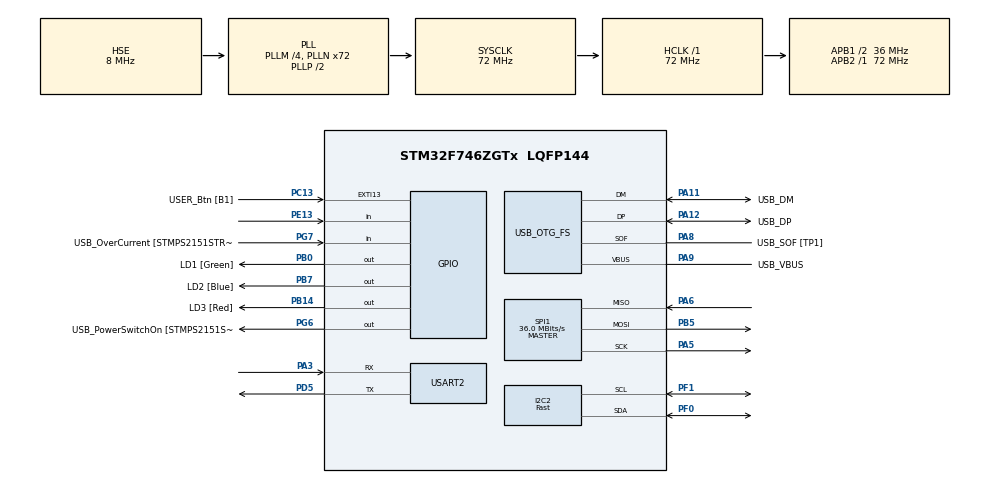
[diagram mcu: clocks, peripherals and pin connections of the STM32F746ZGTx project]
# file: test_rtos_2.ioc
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FREERTOS.Tasks01=defaultTask,24,128,StartDefaultTask,Default,NULL,Dynamic,NULL,NULL;myTask02,8,128,Sensor_Reading_Task,Default,NULL,Dynamic,NULL,NULL;myTask03,8,128,StartTask03,Default,NULL,Dynamic,NULL,NULL;myTask04,8,128,StartTask04,Default,NULL,Dynamic,NULL,NULL
I2C2.I2C_Speed_Mode=I2C_Fast
I2C2.Timing=0x00301739
Mcu.Family=STM32F7
Mcu.Name=STM32F746ZGTx
Mcu.Package=LQFP144
NVIC.PriorityGroup=NVIC_PRIORITYGROUP_4
NVIC.TIM1_UP_TIM10_IRQn=true\:0\:0\:false\:false\:true\:false\:false\:true
NVIC.TimeBase=TIM1_UP_TIM10_IRQn
NVIC.TimeBaseIP=TIM1
PA1.GPIO_Label=RMII_REF_CLK [LAN8742A-CZ-TR_REFCLK0]
PA1.Signal=ETH_REF_CLK
PA10.GPIO_Label=USB_ID
PA10.Signal=USB_OTG_FS_ID
PA11.GPIO_Label=USB_DM
PA11.Mode=Device_Only
PA11.Signal=USB_OTG_FS_DM
PA12.GPIO_Label=USB_DP
PA12.Mode=Device_Only
PA12.Signal=USB_OTG_FS_DP
PA13.GPIO_Label=TMS
PA13.Mode=Serial_Wire
PA13.Signal=SYS_JTMS-SWDIO
PA14.GPIO_Label=TCK
PA14.Mode=Serial_Wire
PA14.Signal=SYS_JTCK-SWCLK
PA2.GPIO_Label=RMII_MDIO [LAN8742A-CZ-TR_MDIO]
PA2.Signal=ETH_MDIO
PA3.Mode=Asynchronous
PA3.Signal=USART2_RX
PA5.Mode=Full_Duplex_Master
PA5.Signal=SPI1_SCK
PA6.Mode=Full_Duplex_Master
PA6.Signal=SPI1_MISO
PA7.GPIO_Label=RMII_CRS_DV [LAN8742A-CZ-TR_CRS_DV]
PA7.Signal=ETH_CRS_DV
PA8.GPIO_Label=USB_SOF [TP1]
PA8.Mode=Activate_SOF_FS
PA8.Signal=USB_OTG_FS_SOF
PA9.GPIO_Label=USB_VBUS
PA9.Mode=Activate_VBUS
PA9.Signal=USB_OTG_FS_VBUS
PB0.GPIO_Label=LD1 [Green]
PB0.Signal=GPIO_Output
PB13.GPIO_Label=RMII_TXD1 [LAN8742A-CZ-TR_TXD1]
PB13.Signal=ETH_TXD1
PB14.GPIO_Label=LD3 [Red]
PB14.Signal=GPIO_Output
PB3.GPIO_Label=SW0
PB3.Signal=SYS_JTDO-SWO
PB5.Mode=Full_Duplex_Master
PB5.Signal=SPI1_MOSI
PB7.GPIO_Label=LD2 [Blue]
PB7.Signal=GPIO_Output
PC1.GPIO_Label=RMII_MDC [LAN8742A-CZ-TR_MDC]
PC1.Signal=ETH_MDC
PC13.GPIO_Label=USER_Btn [B1]
PC13.Signal=GPXTI13
PC14/OSC32_IN.Mode=LSE-External-Oscillator
PC14/OSC32_IN.Signal=RCC_OSC32_IN
PC15/OSC32_OUT.Mode=LSE-External-Oscillator
PC15/OSC32_OUT.Signal=RCC_OSC32_OUT
PC4.GPIO_Label=RMII_RXD0 [LAN8742A-CZ-TR_RXD0]
PC4.Signal=ETH_RXD0
PC5.GPIO_Label=RMII_RXD1 [LAN8742A-CZ-TR_RXD1]
PC5.Signal=ETH_RXD1
PD5.Mode=Asynchronous
PD5.Signal=USART2_TX
PD8.GPIO_Label=STLK_RX [STM32F103CBT6_PA3]
PD8.Signal=USART3_TX
PD9.GPIO_Label=STLK_TX [STM32F103CBT6_PA2]
PD9.Signal=USART3_RX
PE13.Signal=GPIO_Input
PF0.Mode=I2C
PF0.Signal=I2C2_SDA
PF1.Mode=I2C
PF1.Signal=I2C2_SCL
PG11.GPIO_Label=RMII_TX_EN [LAN8742A-CZ-TR_TXEN]
PG11.Signal=ETH_TX_EN
PG13.GPIO_Label=RMII_TXD0 [LAN8742A-CZ-TR_TXD0]
PG13.Signal=ETH_TXD0
PG6.GPIO_Label=USB_PowerSwitchOn [STMPS2151STR_EN]
PG6.Signal=GPIO_Output
PG7.GPIO_Label=USB_OverCurrent [STMPS2151STR_FAULT]
PG7.Signal=GPIO_Input
PH0/OSC_IN.GPIO_Label=MCO [STM32F103CBT6_PA8]
PH0/OSC_IN.Mode=HSE-External-Clock-Source
PH0/OSC_IN.Signal=RCC_OSC_IN
PH1/OSC_OUT.Mode=HSE-External-Clock-Source
PH1/OSC_OUT.Signal=RCC_OSC_OUT
ProjectManager.HeapSize=0x200
ProjectManager.StackSize=0x400
ProjectManager.TargetToolchain=Makefile
RCC.48MHZClocksFreq_Value=24000000
RCC.AHBFreq_Value=72000000
RCC.APB1CLKDivider=RCC_HCLK_DIV2
RCC.APB1Freq_Value=36000000
RCC.APB1TimFreq_Value=72000000
RCC.APB2Freq_Value=72000000
RCC.APB2TimFreq_Value=72000000
RCC.CortexFreq_Value=72000000
RCC.HCLKFreq_Value=72000000
RCC.HSE_VALUE=8000000
RCC.HSI_VALUE=16000000
RCC.PLLM=4
RCC.PLLMUL=RCC_PLL_MUL9
RCC.PLLN=72
RCC.PLLQ=3
RCC.PRESCALERUSB=RCC_USBCLKSOURCE_PLL_DIV1_5
RCC.SYSCLKFreq_VALUE=72000000
RCC.SYSCLKSource=RCC_SYSCLKSOURCE_PLLCLK
RCC.SYSCLKSourceVirtual=RCC_SYSCLKSOURCE_PLLCLK
RCC.USBFreq_Value=48000000
RCC.VCOOutputFreq_Value=144000000
SPI1.CLKPhase=SPI_PHASE_2EDGE
SPI1.CalculateBaudRate=36.0 MBits/s
SPI1.DataSize=SPI_DATASIZE_16BIT
SPI1.Direction=SPI_DIRECTION_2LINES
SPI1.Mode=SPI_MODE_MASTER
SPI1.VirtualType=VM_MASTER
USART2.VirtualMode-Asynchronous=VM_ASYNC
USB_OTG_FS.VirtualMode=Device_Only
VP_FREERTOS_VS_CMSIS_V2.Mode=CMSIS_V2
VP_SYS_VS_tim1.Mode=TIM1
board=NUCLEO-F746ZG

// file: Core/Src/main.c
/* USER CODE BEGIN Header */
/**
  ******************************************************************************
  * @file           : main.c
  * @brief          : Main program body
  ******************************************************************************
  * @attention
  *
  * <h2><center>&copy; Copyright (c) 2022 STMicroelectronics.
  * All rights reserved.</center></h2>
  *
  * This software component is licensed by ST under Ultimate Liberty license
  * SLA0044, the "License"; You may not use this file except in compliance with
  * the License. You may obtain a copy of the License at:
  *                             www.st.com/SLA0044
  *
  ******************************************************************************
  */
/* USER CODE END Header */
#include "main.h"
#include "stdio.h"
#include "cmsis_os.h"
#include "ds18b20.h"
#include "dwt_delay.h"

I2C_HandleTypeDef hi2c2;

SPI_HandleTypeDef hspi1;

UART_HandleTypeDef huart2;

PCD_HandleTypeDef hpcd_USB_OTG_FS;

/* Definitions for defaultTask */
osThreadId_t defaultTaskHandle;
const osThreadAttr_t defaultTask_attributes = {
  .name = "defaultTask",
  .stack_size = 128 * 4,
  .priority = (osPriority_t) osPriorityNormal,
};
/* Definitions for myTask02 */
osThreadId_t myTask02Handle;
const osThreadAttr_t myTask02_attributes = {
  .name = "myTask02",
  .stack_size = 128 * 4,
  .priority = (osPriority_t) osPriorityLow,
};
/* Definitions for myTask03 */
osThreadId_t myTask03Handle;
const osThreadAttr_t myTask03_attributes = {
  .name = "myTask03",
  .stack_size = 128 * 4,
  .priority = (osPriority_t) osPriorityLow,
};
/* Definitions for myTask04 */
osThreadId_t myTask04Handle;
const osThreadAttr_t myTask04_attributes = {
  .name = "myTask04",
  .stack_size = 128 * 4,
  .priority = (osPriority_t) osPriorityLow,
};

void SystemClock_Config(void);
static void MX_GPIO_Init(void);
static void MX_USB_OTG_FS_PCD_Init(void);
static void MX_USART2_UART_Init(void);
static void MX_I2C2_Init(void);
static void MX_SPI1_Init(void);
void StartDefaultTask(void *argument);
void Sensor_Reading_Task(void *argument);
void StartTask03(void *argument);
void StartTask04(void *argument);

int main(void)
{

  /* MCU Configuration--------------------------------------------------------*/

  /* Reset of all peripherals, Initializes the Flash interface and the Systick. */
  HAL_Init();

  /* Configure the system clock */
  SystemClock_Config();

  /* Initialize all configured peripherals */
  MX_GPIO_Init();
  MX_USB_OTG_FS_PCD_Init();
  MX_USART2_UART_Init();
  MX_I2C2_Init();
  MX_SPI1_Init();

  /* Init scheduler */
  osKernelInitialize();

  /* Create the thread(s) */
  /* creation of defaultTask */
  defaultTaskHandle = osThreadNew(StartDefaultTask, NULL, &defaultTask_attributes);

  /* creation of myTask02 */
  myTask02Handle = osThreadNew(Sensor_Reading_Task, NULL, &myTask02_attributes);

  /* creation of myTask03 */
  myTask03Handle = osThreadNew(StartTask03, NULL, &myTask03_attributes);

  /* creation of myTask04 */
  myTask04Handle = osThreadNew(StartTask04, NULL, &myTask04_attributes);

  /* Start scheduler */
  osKernelStart();

  /* We should never get here as control is now taken by the scheduler */
  /* Infinite loop */
  while (1)
  {

  }
}

void SystemClock_Config(void)
{
  RCC_OscInitTypeDef RCC_OscInitStruct = {0};
  RCC_ClkInitTypeDef RCC_ClkInitStruct = {0};
  RCC_PeriphCLKInitTypeDef PeriphClkInitStruct = {0};

  /** Configure LSE Drive Capability
  */
  HAL_PWR_EnableBkUpAccess();
  /** Configure the main internal regulator output voltage
  */
  __HAL_RCC_PWR_CLK_ENABLE();
  __HAL_PWR_VOLTAGESCALING_CONFIG(PWR_REGULATOR_VOLTAGE_SCALE3);
  /** Initializes the RCC Oscillators according to the specified parameters
  * in the RCC_OscInitTypeDef structure.
  */
  RCC_OscInitStruct.OscillatorType = RCC_OSCILLATORTYPE_HSE;
  RCC_OscInitStruct.HSEState = RCC_HSE_BYPASS;
  RCC_OscInitStruct.PLL.PLLState = RCC_PLL_ON;
  RCC_OscInitStruct.PLL.PLLSource = RCC_PLLSOURCE_HSE;
  RCC_OscInitStruct.PLL.PLLM = 4;
  RCC_OscInitStruct.PLL.PLLN = 72;
  RCC_OscInitStruct.PLL.PLLP = RCC_PLLP_DIV2;
  RCC_OscInitStruct.PLL.PLLQ = 3;
  if (HAL_RCC_OscConfig(&RCC_OscInitStruct) != HAL_OK)
  {
    Error_Handler();
  }
  /** Initializes the CPU, AHB and APB buses clocks
  */
  RCC_ClkInitStruct.ClockType = RCC_CLOCKTYPE_HCLK|RCC_CLOCKTYPE_SYSCLK
                              |RCC_CLOCKTYPE_PCLK1|RCC_CLOCKTYPE_PCLK2;
  RCC_ClkInitStruct.SYSCLKSource = RCC_SYSCLKSOURCE_PLLCLK;
  RCC_ClkInitStruct.AHBCLKDivider = RCC_SYSCLK_DIV1;
  RCC_ClkInitStruct.APB1CLKDivider = RCC_HCLK_DIV2;
  RCC_ClkInitStruct.APB2CLKDivider = RCC_HCLK_DIV1;

  if (HAL_RCC_ClockConfig(&RCC_ClkInitStruct, FLASH_LATENCY_2) != HAL_OK)
  {
    Error_Handler();
  }
  PeriphClkInitStruct.PeriphClockSelection = RCC_PERIPHCLK_USART2|RCC_PERIPHCLK_I2C2
                              |RCC_PERIPHCLK_CLK48;
  PeriphClkInitStruct.Usart2ClockSelection = RCC_USART2CLKSOURCE_PCLK1;
  PeriphClkInitStruct.I2c2ClockSelection = RCC_I2C2CLKSOURCE_PCLK1;
  PeriphClkInitStruct.Clk48ClockSelection = RCC_CLK48SOURCE_PLL;
  if (HAL_RCCEx_PeriphCLKConfig(&PeriphClkInitStruct) != HAL_OK)
  {
    Error_Handler();
  }
}

static void MX_I2C2_Init(void)
{

  hi2c2.Instance = I2C2;
  hi2c2.Init.Timing = 0x00301739;
  hi2c2.Init.OwnAddress1 = 0;
  hi2c2.Init.AddressingMode = I2C_ADDRESSINGMODE_7BIT;
  hi2c2.Init.DualAddressMode = I2C_DUALADDRESS_DISABLE;
  hi2c2.Init.OwnAddress2 = 0;
  hi2c2.Init.OwnAddress2Masks = I2C_OA2_NOMASK;
  hi2c2.Init.GeneralCallMode = I2C_GENERALCALL_DISABLE;
  hi2c2.Init.NoStretchMode = I2C_NOSTRETCH_DISABLE;
  if (HAL_I2C_Init(&hi2c2) != HAL_OK)
  {
    Error_Handler();
  }
  /** Configure Analogue filter
  */
  if (HAL_I2CEx_ConfigAnalogFilter(&hi2c2, I2C_ANALOGFILTER_ENABLE) != HAL_OK)
  {
    Error_Handler();
  }
  /** Configure Digital filter
  */
  if (HAL_I2CEx_ConfigDigitalFilter(&hi2c2, 0) != HAL_OK)
  {
    Error_Handler();
  }

}

static void MX_SPI1_Init(void)
{

  /* SPI1 parameter configuration*/
  hspi1.Instance = SPI1;
  hspi1.Init.Mode = SPI_MODE_MASTER;
  hspi1.Init.Direction = SPI_DIRECTION_2LINES;
  hspi1.Init.DataSize = SPI_DATASIZE_16BIT;
  hspi1.Init.CLKPolarity = SPI_POLARITY_LOW;
  hspi1.Init.CLKPhase = SPI_PHASE_2EDGE;
  hspi1.Init.NSS = SPI_NSS_SOFT;
  hspi1.Init.BaudRatePrescaler = SPI_BAUDRATEPRESCALER_2;
  hspi1.Init.FirstBit = SPI_FIRSTBIT_MSB;
  hspi1.Init.TIMode = SPI_TIMODE_DISABLE;
  hspi1.Init.CRCCalculation = SPI_CRCCALCULATION_DISABLE;
  hspi1.Init.CRCPolynomial = 7;
  hspi1.Init.CRCLength = SPI_CRC_LENGTH_DATASIZE;
  hspi1.Init.NSSPMode = SPI_NSS_PULSE_DISABLE;
  if (HAL_SPI_Init(&hspi1) != HAL_OK)
  {
    Error_Handler();
  }

}

static void MX_USART2_UART_Init(void)
{

  huart2.Instance = USART2;
  huart2.Init.BaudRate = 115200;
  huart2.Init.WordLength = UART_WORDLENGTH_8B;
  huart2.Init.StopBits = UART_STOPBITS_1;
  huart2.Init.Parity = UART_PARITY_NONE;
  huart2.Init.Mode = UART_MODE_TX_RX;
  huart2.Init.HwFlowCtl = UART_HWCONTROL_NONE;
  huart2.Init.OverSampling = UART_OVERSAMPLING_16;
  huart2.Init.OneBitSampling = UART_ONE_BIT_SAMPLE_DISABLE;
  huart2.AdvancedInit.AdvFeatureInit = UART_ADVFEATURE_NO_INIT;
  if (HAL_UART_Init(&huart2) != HAL_OK)
  {
    Error_Handler();
  }

}

static void MX_USB_OTG_FS_PCD_Init(void)
{

  hpcd_USB_OTG_FS.Instance = USB_OTG_FS;
  hpcd_USB_OTG_FS.Init.dev_endpoints = 6;
  hpcd_USB_OTG_FS.Init.speed = PCD_SPEED_FULL;
  hpcd_USB_OTG_FS.Init.dma_enable = DISABLE;
  hpcd_USB_OTG_FS.Init.phy_itface = PCD_PHY_EMBEDDED;
  hpcd_USB_OTG_FS.Init.Sof_enable = ENABLE;
  hpcd_USB_OTG_FS.Init.low_power_enable = DISABLE;
  hpcd_USB_OTG_FS.Init.lpm_enable = DISABLE;
  hpcd_USB_OTG_FS.Init.vbus_sensing_enable = ENABLE;
  hpcd_USB_OTG_FS.Init.use_dedicated_ep1 = DISABLE;
  if (HAL_PCD_Init(&hpcd_USB_OTG_FS) != HAL_OK)
  {
    Error_Handler();
  }

}

static void MX_GPIO_Init(void)
{
  GPIO_InitTypeDef GPIO_InitStruct = {0};

  /* GPIO Ports Clock Enable */
  __HAL_RCC_GPIOC_CLK_ENABLE();
  __HAL_RCC_GPIOF_CLK_ENABLE();
  __HAL_RCC_GPIOH_CLK_ENABLE();
  __HAL_RCC_GPIOA_CLK_ENABLE();
  __HAL_RCC_GPIOB_CLK_ENABLE();
  __HAL_RCC_GPIOE_CLK_ENABLE();
  __HAL_RCC_GPIOD_CLK_ENABLE();
  __HAL_RCC_GPIOG_CLK_ENABLE();

  /*Configure GPIO pin Output Level */
  HAL_GPIO_WritePin(GPIOB, LD1_Pin|LD3_Pin|LD2_Pin, GPIO_PIN_RESET);

  /*Configure GPIO pin Output Level */
  HAL_GPIO_WritePin(USB_PowerSwitchOn_GPIO_Port, USB_PowerSwitchOn_Pin, GPIO_PIN_RESET);

  /*Configure GPIO pin : USER_Btn_Pin */
  GPIO_InitStruct.Pin = USER_Btn_Pin;
  GPIO_InitStruct.Mode = GPIO_MODE_IT_RISING;
  GPIO_InitStruct.Pull = GPIO_NOPULL;
  HAL_GPIO_Init(USER_Btn_GPIO_Port, &GPIO_InitStruct);

  /*Configure GPIO pins : RMII_MDC_Pin RMII_RXD0_Pin RMII_RXD1_Pin */
  GPIO_InitStruct.Pin = RMII_MDC_Pin|RMII_RXD0_Pin|RMII_RXD1_Pin;
  GPIO_InitStruct.Mode = GPIO_MODE_AF_PP;
  GPIO_InitStruct.Pull = GPIO_NOPULL;
  GPIO_InitStruct.Speed = GPIO_SPEED_FREQ_VERY_HIGH;
  GPIO_InitStruct.Alternate = GPIO_AF11_ETH;
  HAL_GPIO_Init(GPIOC, &GPIO_InitStruct);

  /*Configure GPIO pins : RMII_REF_CLK_Pin RMII_MDIO_Pin RMII_CRS_DV_Pin */
  GPIO_InitStruct.Pin = RMII_REF_CLK_Pin|RMII_MDIO_Pin|RMII_CRS_DV_Pin;
  GPIO_InitStruct.Mode = GPIO_MODE_AF_PP;
  GPIO_InitStruct.Pull = GPIO_NOPULL;
  GPIO_InitStruct.Speed = GPIO_SPEED_FREQ_VERY_HIGH;
  GPIO_InitStruct.Alternate = GPIO_AF11_ETH;
  HAL_GPIO_Init(GPIOA, &GPIO_InitStruct);

  /*Configure GPIO pins : LD1_Pin LD3_Pin LD2_Pin */
  GPIO_InitStruct.Pin = LD1_Pin|LD3_Pin|LD2_Pin;
  GPIO_InitStruct.Mode = GPIO_MODE_OUTPUT_PP;
  GPIO_InitStruct.Pull = GPIO_NOPULL;
  GPIO_InitStruct.Speed = GPIO_SPEED_FREQ_LOW;
  HAL_GPIO_Init(GPIOB, &GPIO_InitStruct);

  /*Configure GPIO pin : PE13 */
  GPIO_InitStruct.Pin = GPIO_PIN_13;
  GPIO_InitStruct.Mode = GPIO_MODE_INPUT;
  GPIO_InitStruct.Pull = GPIO_NOPULL;
  HAL_GPIO_Init(GPIOE, &GPIO_InitStruct);

  /*Configure GPIO pin : RMII_TXD1_Pin */
  GPIO_InitStruct.Pin = RMII_TXD1_Pin;
  GPIO_InitStruct.Mode = GPIO_MODE_AF_PP;
  GPIO_InitStruct.Pull = GPIO_NOPULL;
  GPIO_InitStruct.Speed = GPIO_SPEED_FREQ_VERY_HIGH;
  GPIO_InitStruct.Alternate = GPIO_AF11_ETH;
  HAL_GPIO_Init(RMII_TXD1_GPIO_Port, &GPIO_InitStruct);

  /*Configure GPIO pins : STLK_RX_Pin STLK_TX_Pin */
  GPIO_InitStruct.Pin = STLK_RX_Pin|STLK_TX_Pin;
  GPIO_InitStruct.Mode = GPIO_MODE_AF_PP;
  GPIO_InitStruct.Pull = GPIO_NOPULL;
  GPIO_InitStruct.Speed = GPIO_SPEED_FREQ_VERY_HIGH;
  GPIO_InitStruct.Alternate = GPIO_AF7_USART3;
  HAL_GPIO_Init(GPIOD, &GPIO_InitStruct);

  /*Configure GPIO pin : USB_PowerSwitchOn_Pin */
  GPIO_InitStruct.Pin = USB_PowerSwitchOn_Pin;
  GPIO_InitStruct.Mode = GPIO_MODE_OUTPUT_PP;
  GPIO_InitStruct.Pull = GPIO_NOPULL;
  GPIO_InitStruct.Speed = GPIO_SPEED_FREQ_LOW;
  HAL_GPIO_Init(USB_PowerSwitchOn_GPIO_Port, &GPIO_InitStruct);

  /*Configure GPIO pin : USB_OverCurrent_Pin */
  GPIO_InitStruct.Pin = USB_OverCurrent_Pin;
  GPIO_InitStruct.Mode = GPIO_MODE_INPUT;
  GPIO_InitStruct.Pull = GPIO_NOPULL;
  HAL_GPIO_Init(USB_OverCurrent_GPIO_Port, &GPIO_InitStruct);

  /*Configure GPIO pins : RMII_TX_EN_Pin RMII_TXD0_Pin */
  GPIO_InitStruct.Pin = RMII_TX_EN_Pin|RMII_TXD0_Pin;
  GPIO_InitStruct.Mode = GPIO_MODE_AF_PP;
  GPIO_InitStruct.Pull = GPIO_NOPULL;
  GPIO_InitStruct.Speed = GPIO_SPEED_FREQ_VERY_HIGH;
  GPIO_InitStruct.Alternate = GPIO_AF11_ETH;
  HAL_GPIO_Init(GPIOG, &GPIO_InitStruct);

}

void StartDefaultTask(void *argument)
{
  for(;;)
  {
    osDelay(1);
  }
}

void Sensor_Reading_Task(void *argument)
{
  /* USER CODE BEGIN Sensor_Reading_Task */
  /* Infinite loop */
  for(;;)
  {
   // HAL_GPIO_TogglePin(LD3_GPIO_Port,LD3_Pin);

   float ds18b20_temp  = ds18b20_output();
   printf("temp : %f \n",ds18b20_temp);  // will be deleted!!
   HAL_Delay(1000);

    //osDelay(1);
  }
  /* USER CODE END Sensor_Reading_Task */
}

void StartTask03(void *argument)
{
  for(;;)
  {
    osDelay(1);
  }
}

void StartTask04(void *argument)
{
  for(;;)
  {
    osDelay(1);
  }
}

 /**
  * @brief  Period elapsed callback in non blocking mode
  * @note   This function is called  when TIM1 interrupt took place, inside
  * HAL_TIM_IRQHandler(). It makes a direct call to HAL_IncTick() to increment
  * a global variable "uwTick" used as application time base.
  * @param  htim : TIM handle
  * @retval None
  */
void HAL_TIM_PeriodElapsedCallback(TIM_HandleTypeDef *htim)
{
  if (htim->Instance == TIM1) {
    HAL_IncTick();
  }
}

void Error_Handler(void)
{
  __disable_irq();
  while (1)
  {
  }
}

/************************ (C) COPYRIGHT STMicroelectronics *****END OF FILE****/
